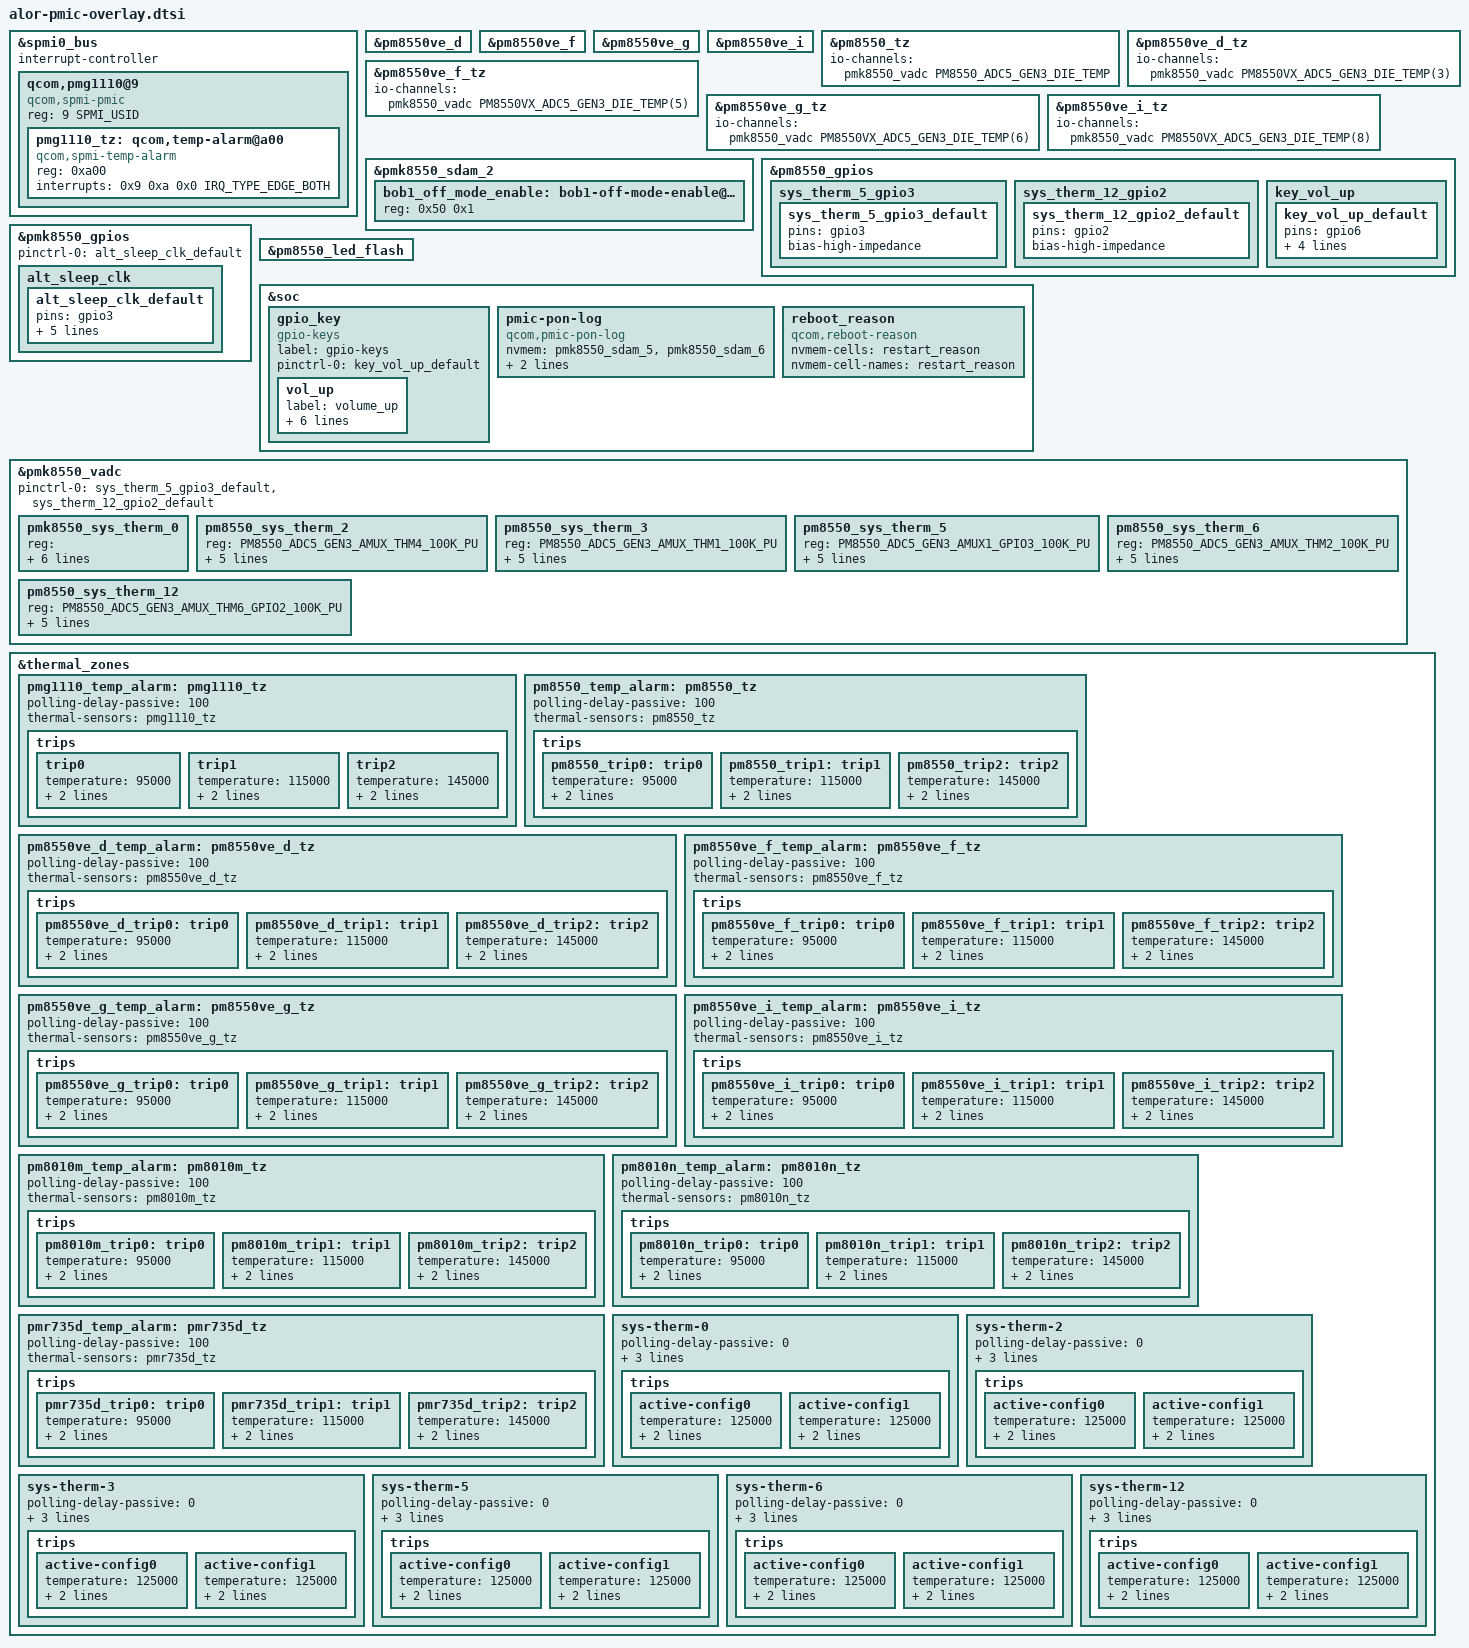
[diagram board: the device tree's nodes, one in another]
// SPDX-License-Identifier: BSD-3-Clause
/*
 * Copyright (c) Qualcomm Technologies, Inc. and/or its subsidiaries.
 */

#include <dt-bindings/gpio/gpio.h>

&spmi0_bus {
	#include "pmk8550.dtsi"
	#include "pm8550.dtsi"
	#include "pm8550ve.dtsi"
	#include "pmr735d.dtsi"
	#include "pm8010.dtsi"
};

&pm8550ve_d {
	status = "ok";
};

&pm8550ve_f {
	status = "ok";
};

&pm8550ve_g {
	status = "ok";
};

&pm8550ve_i {
	status = "ok";
};

&pm8550_tz {
	io-channels = <&pmk8550_vadc PM8550_ADC5_GEN3_DIE_TEMP>;
	io-channel-names = "thermal";
};

&pm8550ve_d_tz {
	io-channels = <&pmk8550_vadc PM8550VX_ADC5_GEN3_DIE_TEMP(3)>;
	io-channel-names = "thermal";
};

&pm8550ve_f_tz {
	io-channels = <&pmk8550_vadc PM8550VX_ADC5_GEN3_DIE_TEMP(5)>;
	io-channel-names = "thermal";
};

&pm8550ve_g_tz {
	io-channels = <&pmk8550_vadc PM8550VX_ADC5_GEN3_DIE_TEMP(6)>;
	io-channel-names = "thermal";
};

&pm8550ve_i_tz {
	io-channels = <&pmk8550_vadc PM8550VX_ADC5_GEN3_DIE_TEMP(8)>;
	io-channel-names = "thermal";
};

&pmk8550_sdam_2 {
	bob1_off_mode_enable: bob1-off-mode-enable@50 {
		reg = <0x50 0x1>;
	};
};

&pm8550_gpios {
	sys_therm_5_gpio3 {
		sys_therm_5_gpio3_default: sys_therm_5_gpio3_default {
			pins = "gpio3";
			bias-high-impedance;
		};
	};

	sys_therm_12_gpio2 {
		sys_therm_12_gpio2_default: sys_therm_12_gpio2_default {
			pins = "gpio2";
			bias-high-impedance;
		};
	};
};

&pmk8550_gpios {
	pinctrl-0 = <&alt_sleep_clk_default>;
	pinctrl-names = "default";

	alt_sleep_clk {
		alt_sleep_clk_default: alt_sleep_clk_default {
			pins = "gpio3";
			function = "func1";
			input-disable;
			output-enable;
			bias-disable;
			power-source = <0>;
		};
	};
};

&spmi0_bus {
	#address-cells = <2>;
	#size-cells = <0>;
	interrupt-controller;
	#interrupt-cells = <4>;

	qcom,pmg1110@9 {
		compatible = "qcom,spmi-pmic";
		reg = <9 SPMI_USID>;
		#address-cells = <1>;
		#size-cells = <0>;

		pmg1110_tz: qcom,temp-alarm@a00 {
			compatible = "qcom,spmi-temp-alarm";
			reg = <0xa00>;
			interrupts = <0x9 0xa 0x0 IRQ_TYPE_EDGE_BOTH>;
			#thermal-sensor-cells = <0>;
		};
	};
};

&pm8550_led_flash {
	status = "ok";
};

&pm8550_gpios {
	key_vol_up {
		key_vol_up_default: key_vol_up_default {
			pins = "gpio6";
			function = "normal";
			input-enable;
			bias-pull-up;
			power-source = <1>;
		};
	};
};

&soc {
	gpio_key {
		compatible = "gpio-keys";
		label = "gpio-keys";
		pinctrl-names = "default";
		pinctrl-0 = <&key_vol_up_default>;
		vol_up {
			label = "volume_up";
			gpios = <&pm8550_gpios 6 GPIO_ACTIVE_LOW>;
			linux,input-type = <1>;
			linux,code = <KEY_VOLUMEUP>;
			gpio-key,wakeup;
			debounce-interval = <15>;
			linux,can-disable;
		};
	};

	pmic-pon-log {
		compatible = "qcom,pmic-pon-log";
		nvmem = <&pmk8550_sdam_5>, <&pmk8550_sdam_6>;
		nvmem-names = "pon_log0", "pon_log1";
		depends-on-supply = <&wdog>;
	};
};

&pmk8550_vadc {
	pinctrl-0 = <&sys_therm_5_gpio3_default>, <&sys_therm_12_gpio2_default>;
	pinctrl-names = "default";

	pmk8550_sys_therm_0 {
		reg = <PMK8550_ADC5_GEN3_AMUX_THM1_XO_THERM_100K_PU>;
		label = "pmk8550_sys_therm_0";
		qcom,ratiometric;
		qcom,hw-settle-time = <200>;
		qcom,pre-scaling = <1 1>;
		qcom,adc-tm-type = <1>;
	};

	pm8550_sys_therm_2 {
		reg = <PM8550_ADC5_GEN3_AMUX_THM4_100K_PU>;
		label = "pm8550_sys_therm_2";
		qcom,ratiometric;
		qcom,hw-settle-time = <200>;
		qcom,pre-scaling = <1 1>;
		qcom,adc-tm-type = <1>;
	};

	pm8550_sys_therm_3 {
		reg = <PM8550_ADC5_GEN3_AMUX_THM1_100K_PU>;
		label = "pm8550_sys_therm_3";
		qcom,ratiometric;
		qcom,hw-settle-time = <200>;
		qcom,pre-scaling = <1 1>;
		qcom,adc-tm-type = <1>;
	};

	pm8550_sys_therm_5 {
		reg = <PM8550_ADC5_GEN3_AMUX1_GPIO3_100K_PU>;
		label = "pm8550_sys_therm_5";
		qcom,ratiometric;
		qcom,hw-settle-time = <200>;
		qcom,pre-scaling = <1 1>;
		qcom,adc-tm-type = <1>;
	};

	pm8550_sys_therm_6 {
		reg = <PM8550_ADC5_GEN3_AMUX_THM2_100K_PU>;
		label = "pm8550_sys_therm_6";
		qcom,ratiometric;
		qcom,hw-settle-time = <200>;
		qcom,pre-scaling = <1 1>;
		qcom,adc-tm-type = <1>;
	};

	pm8550_sys_therm_12 {
		reg = <PM8550_ADC5_GEN3_AMUX_THM6_GPIO2_100K_PU>;
		label = "pm8550_sys_therm_12";
		qcom,ratiometric;
		qcom,hw-settle-time = <200>;
		qcom,pre-scaling = <1 1>;
		qcom,adc-tm-type = <1>;
	};
};

&thermal_zones {
	pmg1110_temp_alarm: pmg1110_tz {
		polling-delay-passive = <100>;
		thermal-sensors = <&pmg1110_tz>;

		trips {
			trip0 {
				temperature = <95000>;
				hysteresis = <0>;
				type = "passive";
			};

			trip1 {
				temperature = <115000>;
				hysteresis = <0>;
				type = "critical";
			};

			trip2 {
				temperature = <145000>;
				hysteresis = <0>;
				type = "critical";
			};
		};
	};

	pm8550_temp_alarm: pm8550_tz {
		polling-delay-passive = <100>;
		thermal-sensors = <&pm8550_tz>;

		trips {
			pm8550_trip0: trip0 {
				temperature = <95000>;
				hysteresis = <0>;
				type = "passive";
			};

			pm8550_trip1: trip1 {
				temperature = <115000>;
				hysteresis = <0>;
				type = "hot";
			};

			pm8550_trip2: trip2 {
				temperature = <145000>;
				hysteresis = <0>;
				type = "critical";
			};
		};
	};

	pm8550ve_d_temp_alarm: pm8550ve_d_tz {
		polling-delay-passive = <100>;
		thermal-sensors = <&pm8550ve_d_tz>;

		trips {
			pm8550ve_d_trip0: trip0 {
				temperature = <95000>;
				hysteresis = <0>;
				type = "passive";
			};

			pm8550ve_d_trip1: trip1 {
				temperature = <115000>;
				hysteresis = <0>;
				type = "hot";
			};

			pm8550ve_d_trip2: trip2 {
				temperature = <145000>;
				hysteresis = <0>;
				type = "critical";
			};
		};
	};

	pm8550ve_f_temp_alarm: pm8550ve_f_tz {
		polling-delay-passive = <100>;
		thermal-sensors = <&pm8550ve_f_tz>;

		trips {
			pm8550ve_f_trip0: trip0 {
				temperature = <95000>;
				hysteresis = <0>;
				type = "passive";
			};

			pm8550ve_f_trip1: trip1 {
				temperature = <115000>;
				hysteresis = <0>;
				type = "hot";
			};

			pm8550ve_f_trip2: trip2 {
				temperature = <145000>;
				hysteresis = <0>;
				type = "critical";
			};
		};
	};

	pm8550ve_g_temp_alarm: pm8550ve_g_tz {
		polling-delay-passive = <100>;
		thermal-sensors = <&pm8550ve_g_tz>;

		trips {
			pm8550ve_g_trip0: trip0 {
				temperature = <95000>;
				hysteresis = <0>;
				type = "passive";
			};

			pm8550ve_g_trip1: trip1 {
				temperature = <115000>;
				hysteresis = <0>;
				type = "hot";
			};

			pm8550ve_g_trip2: trip2 {
				temperature = <145000>;
				hysteresis = <0>;
				type = "critical";
			};
		};
	};

	pm8550ve_i_temp_alarm: pm8550ve_i_tz {
		polling-delay-passive = <100>;
		thermal-sensors = <&pm8550ve_i_tz>;

		trips {
			pm8550ve_i_trip0: trip0 {
				temperature = <95000>;
				hysteresis = <0>;
				type = "passive";
			};

			pm8550ve_i_trip1: trip1 {
				temperature = <115000>;
				hysteresis = <0>;
				type = "hot";
			};

			pm8550ve_i_trip2: trip2 {
				temperature = <145000>;
				hysteresis = <0>;
				type = "critical";
			};
		};
	};

	pm8010m_temp_alarm: pm8010m_tz {
		polling-delay-passive = <100>;
		thermal-sensors = <&pm8010m_tz>;

		trips {
			pm8010m_trip0: trip0 {
				temperature = <95000>;
				hysteresis = <0>;
				type = "passive";
			};

			pm8010m_trip1: trip1 {
				temperature = <115000>;
				hysteresis = <0>;
				type = "hot";
			};

			pm8010m_trip2: trip2 {
				temperature = <145000>;
				hysteresis = <0>;
				type = "critical";
			};
		};
	};

	pm8010n_temp_alarm: pm8010n_tz {
		polling-delay-passive = <100>;
		thermal-sensors = <&pm8010n_tz>;

		trips {
			pm8010n_trip0: trip0 {
				temperature = <95000>;
				hysteresis = <0>;
				type = "passive";
			};

			pm8010n_trip1: trip1 {
				temperature = <115000>;
				hysteresis = <0>;
				type = "hot";
			};

			pm8010n_trip2: trip2 {
				temperature = <145000>;
				hysteresis = <0>;
				type = "critical";
			};
		};
	};

	pmr735d_temp_alarm: pmr735d_tz {
		polling-delay-passive = <100>;
		thermal-sensors = <&pmr735d_tz>;

		trips {
			pmr735d_trip0: trip0 {
				temperature = <95000>;
				hysteresis = <0>;
				type = "passive";
			};

			pmr735d_trip1: trip1 {
				temperature = <115000>;
				hysteresis = <0>;
				type = "hot";
			};

			pmr735d_trip2: trip2 {
				temperature = <145000>;
				hysteresis = <0>;
				type = "critical";
			};
		};
	};

	sys-therm-0 {
		polling-delay-passive = <0>;
		polling-delay = <0>;
		thermal-sensors = <&pmk8550_vadc PMK8550_ADC5_GEN3_AMUX_THM1_XO_THERM_100K_PU>;

		trips {
			active-config0 {
				temperature = <125000>;
				hysteresis = <1000>;
				type = "passive";
			};

			active-config1 {
				temperature = <125000>;
				hysteresis = <1000>;
				type = "passive";
			};
		};
	};

	sys-therm-2 {
		polling-delay-passive = <0>;
		polling-delay = <0>;
		thermal-sensors = <&pmk8550_vadc PM8550_ADC5_GEN3_AMUX_THM4_100K_PU>;

		trips {
			active-config0 {
				temperature = <125000>;
				hysteresis = <1000>;
				type = "passive";
			};

			active-config1 {
				temperature = <125000>;
				hysteresis = <1000>;
				type = "passive";
			};
		};
	};

	sys-therm-3 {
		polling-delay-passive = <0>;
		polling-delay = <0>;
		thermal-sensors = <&pmk8550_vadc PM8550_ADC5_GEN3_AMUX_THM1_100K_PU>;

		trips {
			active-config0 {
				temperature = <125000>;
				hysteresis = <1000>;
				type = "passive";
			};

			active-config1 {
				temperature = <125000>;
				hysteresis = <1000>;
				type = "passive";
			};
		};
	};

	sys-therm-5 {
		polling-delay-passive = <0>;
		polling-delay = <0>;
		thermal-sensors = <&pmk8550_vadc PM8550_ADC5_GEN3_AMUX1_GPIO3_100K_PU>;

		trips {
			active-config0 {
				temperature = <125000>;
				hysteresis = <1000>;
				type = "passive";
			};

			active-config1 {
				temperature = <125000>;
				hysteresis = <1000>;
				type = "passive";
			};
		};
	};

	sys-therm-6 {
		polling-delay-passive = <0>;
		polling-delay = <0>;
		thermal-sensors = <&pmk8550_vadc PM8550_ADC5_GEN3_AMUX_THM2_100K_PU>;

		trips {
			active-config0 {
				temperature = <125000>;
				hysteresis = <1000>;
				type = "passive";
			};

			active-config1 {
				temperature = <125000>;
				hysteresis = <1000>;
				type = "passive";
			};
		};
	};

	sys-therm-12 {
		polling-delay-passive = <0>;
		polling-delay = <0>;
		thermal-sensors = <&pmk8550_vadc PM8550_ADC5_GEN3_AMUX_THM6_GPIO2_100K_PU>;

		trips {
			active-config0 {
				temperature = <125000>;
				hysteresis = <1000>;
				type = "passive";
			};

			active-config1 {
				temperature = <125000>;
				hysteresis = <1000>;
				type = "passive";
			};
		};
	};
};

&soc {
	reboot_reason {
		compatible = "qcom,reboot-reason";
		nvmem-cells = <&restart_reason>;
		nvmem-cell-names = "restart_reason";
	};
};
